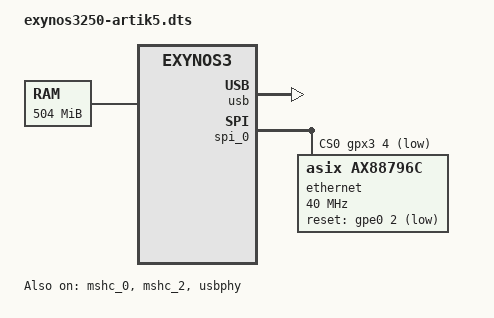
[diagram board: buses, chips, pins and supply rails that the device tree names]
// SPDX-License-Identifier: GPL-2.0+

/dts-v1/;
#include <dt-bindings/gpio/gpio.h>
#include "exynos3250.dtsi"
/ {
	compatible = "samsung,artik5", "samsung,exynos3250", "samsung,exynos3";

    aliases {
    	console = &uart2;
        mmc0 = &mshc_0;
        mmc1 = &mshc_2;
    };

    chosen {
        stdout-path = "/serial@13820000:115200n8";
    };

	memory@40000000 {
		device_type = "memory";
		reg = <0x40000000 0x1f800000>;
		u-boot,dm-pre-reloc;
	};

};

&fin_pll {
	clock-frequency = <24000000>;
};

&mshc_0 {
	status = "okay";
	index = <0>;
	/*
	 * No fast-mode properties on purpose, matching the Linux artik5
	 * DT (which caps this board at 100 MHz). Empirically:
	 * - HS400 fails outright (driver lacks DQS/DLL read-strobe
	 *   support) and wedges the card;
	 * - HS200 tunes and mostly works, but a read-only stress test
	 *   caught silently corrupted 2 MiB reads (~1 per 32 MiB) -
	 *   unacceptable for a boot loader;
	 * - HS 52 MHz is stable (stress-tested).
	 */
};

&mshc_2 {
	status = "okay";
	/*
	 * Must be the hardware channel number (SDMMC2): index feeds
	 * get/set_mmc_clk, which picks the CLK_DIV_FSYS1/2 divider
	 * field from it. With index = <1> the driver programs the
	 * (unused) MMC1 divider and the SD card runs at whatever rate
	 * BL2 left in the MMC2 field - far above the requested 50 MHz,
	 * giving silently corrupted large reads. U-boot device
	 * numbering comes from the mmc1 alias, not from this.
	 */
	index = <2>;
};

&usb {
	status = "okay";
};

&usbphy {
	status = "okay";
};

&spi_0 {
	status = "okay";
	cs-gpios = <&gpx3 4 GPIO_ACTIVE_LOW>;

	ethernet@0 {
		compatible = "asix,ax88796c";
		reg = <0x0>;
		spi-max-frequency = <40000000>;
		reset-gpios = <&gpe0 2 GPIO_ACTIVE_LOW>;
	};
};
